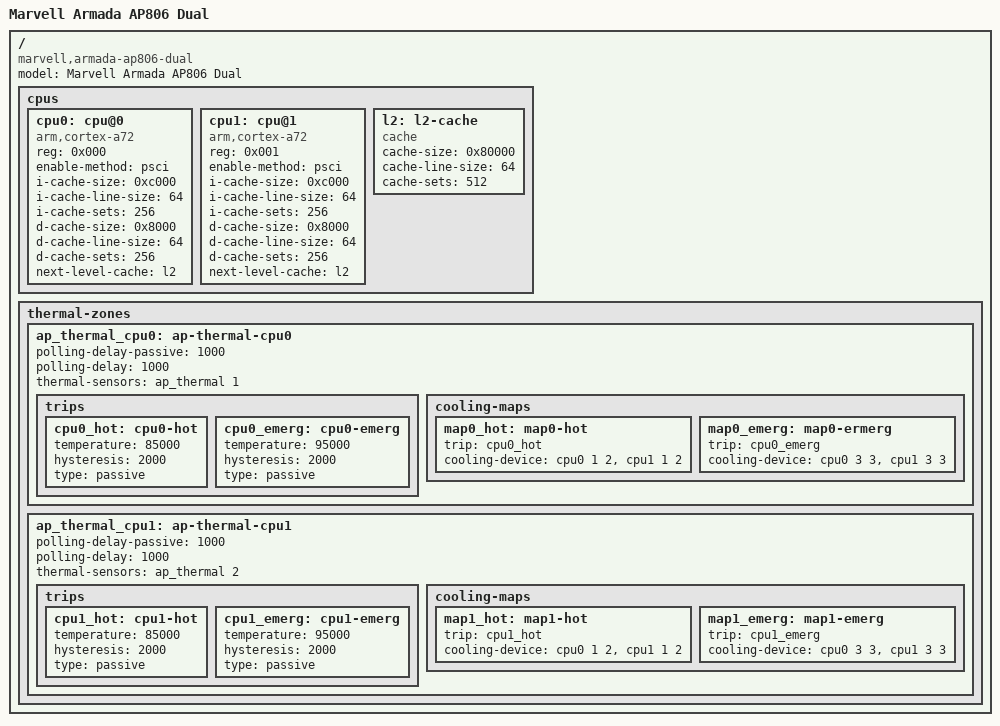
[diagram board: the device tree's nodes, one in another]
// SPDX-License-Identifier: (GPL-2.0+ OR MIT)
/*
 * Copyright (C) 2016 Marvell Technology Group Ltd.
 *
 * Device Tree file for Marvell Armada AP806.
 */

#include "armada-ap806.dtsi"

/ {
	model = "Marvell Armada AP806 Dual";
	compatible = "marvell,armada-ap806-dual", "marvell,armada-ap806";

	cpus {
		#address-cells = <1>;
		#size-cells = <0>;

		cpu0: cpu@0 {
			device_type = "cpu";
			compatible = "arm,cortex-a72", "arm,armv8";
			reg = <0x000>;
			enable-method = "psci";
			#cooling-cells = <2>;
			i-cache-size = <0xc000>;
			i-cache-line-size = <64>;
			i-cache-sets = <256>;
			d-cache-size = <0x8000>;
			d-cache-line-size = <64>;
			d-cache-sets = <256>;
			next-level-cache = <&l2>;
		};
		cpu1: cpu@1 {
			device_type = "cpu";
			compatible = "arm,cortex-a72", "arm,armv8";
			reg = <0x001>;
			enable-method = "psci";
			#cooling-cells = <2>;
			i-cache-size = <0xc000>;
			i-cache-line-size = <64>;
			i-cache-sets = <256>;
			d-cache-size = <0x8000>;
			d-cache-line-size = <64>;
			d-cache-sets = <256>;
			next-level-cache = <&l2>;
		};

		l2: l2-cache {
			compatible = "cache";
			cache-size = <0x80000>;
			cache-line-size = <64>;
			cache-sets = <512>;
		};
	};

	thermal-zones {
		ap_thermal_cpu0: ap-thermal-cpu0 {
			polling-delay-passive = <1000>;
			polling-delay = <1000>;

			thermal-sensors = <&ap_thermal 1>;

			trips {
				cpu0_hot: cpu0-hot {
					temperature = <85000>;
					hysteresis = <2000>;
					type = "passive";
				};
				cpu0_emerg: cpu0-emerg {
					temperature = <95000>;
					hysteresis = <2000>;
					type = "passive";
				};
			};

			cooling-maps {
				map0_hot: map0-hot {
					trip = <&cpu0_hot>;
					cooling-device = <&cpu0 1 2>,
						<&cpu1 1 2>;
				};
				map0_emerg: map0-ermerg {
					trip = <&cpu0_emerg>;
					cooling-device = <&cpu0 3 3>,
						<&cpu1 3 3>;
				};
			};
		};

		ap_thermal_cpu1: ap-thermal-cpu1 {
			polling-delay-passive = <1000>;
			polling-delay = <1000>;

			thermal-sensors = <&ap_thermal 2>;

			trips {
				cpu1_hot: cpu1-hot {
					temperature = <85000>;
					hysteresis = <2000>;
					type = "passive";
				};
				cpu1_emerg: cpu1-emerg {
					temperature = <95000>;
					hysteresis = <2000>;
					type = "passive";
				};
			};

			cooling-maps {
				map1_hot: map1-hot {
					trip = <&cpu1_hot>;
					cooling-device = <&cpu0 1 2>,
						<&cpu1 1 2>;
				};
				map1_emerg: map1-emerg {
					trip = <&cpu1_emerg>;
					cooling-device = <&cpu0 3 3>,
						<&cpu1 3 3>;
				};
			};
		};
	};
};
